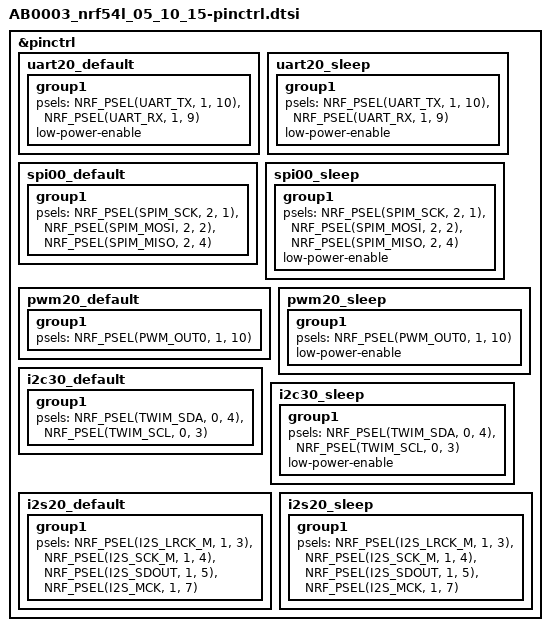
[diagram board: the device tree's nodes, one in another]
/*
 * Copyright (c) 2024 Nordic Semiconductor
 * SPDX-License-Identifier: Apache-2.0
 */

&pinctrl {
	/omit-if-no-ref/ uart20_default: uart20_default {
		group1 {
			psels = <NRF_PSEL(UART_TX, 1, 10)>,
				<NRF_PSEL(UART_RX, 1, 9)>;
				
			low-power-enable;
		};
	};

	/omit-if-no-ref/ uart20_sleep: uart20_sleep {
		group1 {
			psels = <NRF_PSEL(UART_TX, 1, 10)>,
				<NRF_PSEL(UART_RX, 1, 9)>;
				
			low-power-enable;
		};
	};


	/omit-if-no-ref/ spi00_default: spi00_default {
		group1 {
			psels = <NRF_PSEL(SPIM_SCK, 2, 1)>,
				<NRF_PSEL(SPIM_MOSI, 2, 2)>,
				<NRF_PSEL(SPIM_MISO, 2, 4)>;
		};
	};

	/omit-if-no-ref/ spi00_sleep: spi00_sleep {
		group1 {
			psels = <NRF_PSEL(SPIM_SCK, 2, 1)>,
				<NRF_PSEL(SPIM_MOSI, 2, 2)>,
				<NRF_PSEL(SPIM_MISO, 2, 4)>;
				low-power-enable;
		};
	};

	/omit-if-no-ref/ pwm20_default: pwm20_default {
		group1 {
			psels = <NRF_PSEL(PWM_OUT0, 1, 10)>;
		};
	};

	/omit-if-no-ref/ pwm20_sleep: pwm20_sleep {
		group1 {
			psels = <NRF_PSEL(PWM_OUT0, 1, 10)>;
			low-power-enable;
		};
	};

	i2c30_default: i2c30_default {
		group1 {
			psels = <NRF_PSEL(TWIM_SDA, 0, 4)>,
				<NRF_PSEL(TWIM_SCL, 0, 3)>;				
		};
	};

	i2c30_sleep: i2c30_sleep {
		group1 {
			psels = <NRF_PSEL(TWIM_SDA, 0, 4)>,
				<NRF_PSEL(TWIM_SCL, 0, 3)>;
				low-power-enable;
		};
	};

	i2s20_default: i2s20_default {
        group1 {
            psels = <NRF_PSEL(I2S_LRCK_M, 1, 3)>,			
                    <NRF_PSEL(I2S_SCK_M, 1, 4)>,
                    <NRF_PSEL(I2S_SDOUT, 1, 5)>, 
                    <NRF_PSEL(I2S_MCK, 1, 7)>;
                    //<NRF_PSEL(I2S_SDIN, 1, 4)>;
					
        };
    };

	i2s20_sleep: i2s20_sleep {
        group1 {
            psels = <NRF_PSEL(I2S_LRCK_M, 1, 3)>,
                    <NRF_PSEL(I2S_SCK_M, 1, 4)>,
                    <NRF_PSEL(I2S_SDOUT, 1, 5)>,
                    <NRF_PSEL(I2S_MCK, 1, 7)>;
                    //<NRF_PSEL(I2S_SDIN, 1, 4)>;
        };
    };

};
